VERSION ""

NS_ :

BS_:

BU_: XXX

CM_ "2023 Toyota Corolla (TSS 3.0) powertrain -- CAN FD + SecOC.";
CM_ "STATUS: every bit position below is DECODED FROM PASSIVE RLOGS, NOT CONFIRMED.";
CM_ "Validate in cabana against a real rlog before trusting any value. See NOTES.md.";
CM_ "Bit convention: big-endian (@0) value at byte K -> startbit = K*8 + 7.";
CM_ "SECOC_SYNCHRONIZATION copied verbatim from opendbc toyota_secoc_pt.dbc -- do not hand-edit.";
CM_ "DBC name MUST keep the toyota_ prefix: opendbc auto-computes the CHECKSUM signal off it.";

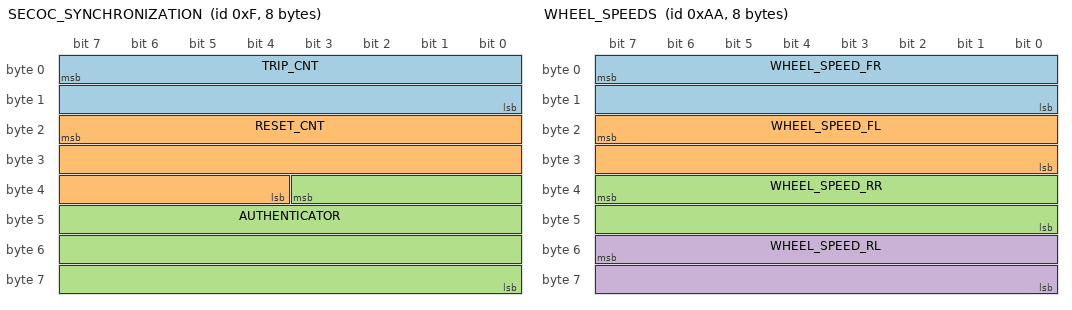
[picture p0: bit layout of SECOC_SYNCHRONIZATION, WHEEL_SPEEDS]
BO_ 15 SECOC_SYNCHRONIZATION: 8 XXX
 SG_ TRIP_CNT : 7|16@0+ (1,0) [0|65535] "" XXX
 SG_ RESET_CNT : 23|20@0+ (1,0) [0|65535] "" XXX
 SG_ AUTHENTICATOR : 35|28@0+ (1,0) [0|268435455] "" XXX

BO_ 48 STEER_ANGLE_SENSOR: 32 XXX
 SG_ STEER_ANGLE : 167|16@0- (0.061,0) [-500|500] "deg" XXX

BO_ 138 STEER_ANGLE_ACC_STATUS: 32 XXX
 SG_ STEER_ANGLE : 151|16@0- (0.061,0) [-500|500] "deg" XXX
 SG_ BYTE24_UNKNOWN : 199|8@0+ (1,0) [0|255] "" XXX
 SG_ ACC_STATE : 63|8@0+ (1,0) [0|255] "" XXX
 SG_ ACC_STANDSTILL : 61|1@0+ (1,0) [0|1] "" XXX
 SG_ ACC_ENGAGED : 180|1@0+ (1,0) [0|1] "" XXX
 SG_ ACC_BUTTON : 167|1@0+ (1,0) [0|1] "" XXX
 SG_ MSG_CNT : 215|8@0+ (1,0) [0|255] "" XXX
 SG_ MAC : 231|32@0+ (1,0) [0|4294967295] "" XXX

BO_ 144 KINEMATICS: 32 XXX
 SG_ YAW_RATE : 100|12@0- (0.02,0) [-100|100] "deg/s" XXX

BO_ 170 WHEEL_SPEEDS: 8 XXX
 SG_ WHEEL_SPEED_FR : 7|16@0+ (0.01,-67.67) [0|250] "km/h" XXX
 SG_ WHEEL_SPEED_FL : 23|16@0+ (0.01,-67.67) [0|250] "km/h" XXX
 SG_ WHEEL_SPEED_RR : 39|16@0+ (0.01,-67.67) [0|250] "km/h" XXX
 SG_ WHEEL_SPEED_RL : 55|16@0+ (0.01,-67.67) [0|250] "km/h" XXX

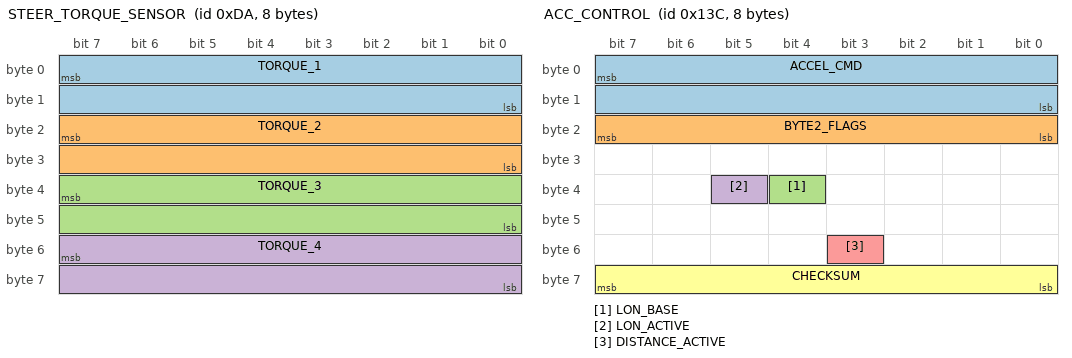
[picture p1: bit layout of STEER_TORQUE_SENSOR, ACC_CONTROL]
BO_ 218 STEER_TORQUE_SENSOR: 8 XXX
 SG_ TORQUE_1 : 7|16@0- (1,0) [-32768|32767] "" XXX
 SG_ TORQUE_2 : 23|16@0- (1,0) [-32768|32767] "" XXX
 SG_ TORQUE_3 : 39|16@0- (1,0) [-32768|32767] "" XXX
 SG_ TORQUE_4 : 55|16@0- (1,0) [-32768|32767] "" XXX

BO_ 278 GAS_PEDAL: 8 XXX
 SG_ GAS_PEDAL_USER : 15|8@0+ (1,0) [0|255] "" XXX

BO_ 257 BRAKE_MODULE: 8 XXX
 SG_ BRAKE_PRESSED : 3|1@0+ (1,0) [0|1] "" XXX
 SG_ BRAKE_PRESSURE : 23|16@0+ (1,0) [0|4095] "" XXX

BO_ 275 ACC_HUD_LEGACY: 8 XXX
 SG_ SET_SPEED : 23|8@0+ (1,0) [0|255] "" XXX

BO_ 316 ACC_CONTROL: 8 XXX
 SG_ ACCEL_CMD : 7|16@0- (0.001,0) [-3.0|1.5] "m/s^2" XXX
 SG_ BYTE2_FLAGS : 23|8@0+ (1,0) [0|255] "" XXX
 SG_ LON_BASE : 36|1@0+ (1,0) [0|1] "" XXX
 SG_ LON_ACTIVE : 37|1@0+ (1,0) [0|1] "" XXX
 SG_ DISTANCE_ACTIVE : 51|1@0+ (1,0) [0|1] "" XXX
 SG_ CHECKSUM : 63|8@0+ (1,0) [0|255] "" XXX

BO_ 593 ACC_HUD: 8 XXX
 SG_ SET_SPEED : 23|8@0+ (1,0) [0|255] "" XXX
 SG_ ACC_ENGAGED_HUD : 6|1@0+ (1,0) [0|1] "" XXX

BO_ 673 GEAR_PACKET: 8 XXX
 SG_ GEAR : 39|8@0+ (1,0) [0|255] "" XXX

BO_ 959 GEAR_PACKET_2: 8 XXX
 SG_ GEAR : 7|8@0+ (1,0) [0|255] "" XXX

BO_ 416 ADAS_STEER_COMMAND: 48 XXX
 SG_ STEER_ANGLE_CMD : 95|16@0- (0.0148,0) [-485|485] "deg" XXX
 SG_ STEER_REQUEST : 54|1@0+ (1,0) [0|1] "" XXX
 SG_ COUNTER : 23|8@0+ (1,0) [0|255] "" XXX
 SG_ BYTE00 : 7|8@0+ (1,0) [0|255] "" XXX
 SG_ BYTE01 : 15|8@0+ (1,0) [0|255] "" XXX
 SG_ BYTE02 : 23|8@0+ (1,0) [0|255] "" XXX
 SG_ BYTE03 : 31|8@0+ (1,0) [0|255] "" XXX
 SG_ BYTE04 : 39|8@0+ (1,0) [0|255] "" XXX
 SG_ BYTE05 : 47|8@0+ (1,0) [0|255] "" XXX
 SG_ BYTE06 : 55|8@0+ (1,0) [0|255] "" XXX
 SG_ BYTE07 : 63|8@0+ (1,0) [0|255] "" XXX
 SG_ BYTE08 : 71|8@0+ (1,0) [0|255] "" XXX
 SG_ BYTE09 : 79|8@0+ (1,0) [0|255] "" XXX
 SG_ BYTE10 : 87|8@0+ (1,0) [0|255] "" XXX
 SG_ BYTE11 : 95|8@0+ (1,0) [0|255] "" XXX
 SG_ BYTE12 : 103|8@0+ (1,0) [0|255] "" XXX
 SG_ BYTE13 : 111|8@0+ (1,0) [0|255] "" XXX
 SG_ BYTE14 : 119|8@0+ (1,0) [0|255] "" XXX
 SG_ BYTE15 : 127|8@0+ (1,0) [0|255] "" XXX
 SG_ BYTE16 : 135|8@0+ (1,0) [0|255] "" XXX
 SG_ BYTE17 : 143|8@0+ (1,0) [0|255] "" XXX
 SG_ BYTE18 : 151|8@0+ (1,0) [0|255] "" XXX
 SG_ BYTE19 : 159|8@0+ (1,0) [0|255] "" XXX
 SG_ BYTE20 : 167|8@0+ (1,0) [0|255] "" XXX
 SG_ BYTE21 : 175|8@0+ (1,0) [0|255] "" XXX
 SG_ BYTE22 : 183|8@0+ (1,0) [0|255] "" XXX
 SG_ BYTE23 : 191|8@0+ (1,0) [0|255] "" XXX
 SG_ BYTE24 : 199|8@0+ (1,0) [0|255] "" XXX
 SG_ BYTE25 : 207|8@0+ (1,0) [0|255] "" XXX
 SG_ BYTE26 : 215|8@0+ (1,0) [0|255] "" XXX
 SG_ BYTE27 : 223|8@0+ (1,0) [0|255] "" XXX
 SG_ BYTE28 : 231|8@0+ (1,0) [0|255] "" XXX
 SG_ BYTE29 : 239|8@0+ (1,0) [0|255] "" XXX
 SG_ BYTE30 : 247|8@0+ (1,0) [0|255] "" XXX
 SG_ BYTE31 : 255|8@0+ (1,0) [0|255] "" XXX
 SG_ BYTE32 : 263|8@0+ (1,0) [0|255] "" XXX
 SG_ BYTE33 : 271|8@0+ (1,0) [0|255] "" XXX
 SG_ BYTE34 : 279|8@0+ (1,0) [0|255] "" XXX
 SG_ BYTE35 : 287|8@0+ (1,0) [0|255] "" XXX
 SG_ BYTE36 : 295|8@0+ (1,0) [0|255] "" XXX
 SG_ BYTE37 : 303|8@0+ (1,0) [0|255] "" XXX
 SG_ BYTE38 : 311|8@0+ (1,0) [0|255] "" XXX
 SG_ BYTE39 : 319|8@0+ (1,0) [0|255] "" XXX
 SG_ BYTE40 : 327|8@0+ (1,0) [0|255] "" XXX
 SG_ BYTE41 : 335|8@0+ (1,0) [0|255] "" XXX
 SG_ BYTE42 : 343|8@0+ (1,0) [0|255] "" XXX
 SG_ BYTE43 : 351|8@0+ (1,0) [0|255] "" XXX
 SG_ BYTE44 : 359|8@0+ (1,0) [0|255] "" XXX
 SG_ BYTE45 : 367|8@0+ (1,0) [0|255] "" XXX
 SG_ BYTE46 : 375|8@0+ (1,0) [0|255] "" XXX
 SG_ BYTE47 : 383|8@0+ (1,0) [0|255] "" XXX

BO_ 352 ADAS_ACC_REQUEST: 32 XXX
 SG_ ACCEL_REQ : 38|15@0- (0.001,0) [-16.384|16.383] "m/s^2" XXX
 SG_ COUNTER : 23|8@0+ (1,0) [0|255] "" XXX
 SG_ BYTE00 : 7|8@0+ (1,0) [0|255] "" XXX
 SG_ BYTE01 : 15|8@0+ (1,0) [0|255] "" XXX
 SG_ BYTE02 : 23|8@0+ (1,0) [0|255] "" XXX
 SG_ BYTE03 : 31|8@0+ (1,0) [0|255] "" XXX
 SG_ BYTE04 : 39|8@0+ (1,0) [0|255] "" XXX
 SG_ BYTE05 : 47|8@0+ (1,0) [0|255] "" XXX
 SG_ BYTE06 : 55|8@0+ (1,0) [0|255] "" XXX
 SG_ BYTE07 : 63|8@0+ (1,0) [0|255] "" XXX
 SG_ BYTE08 : 71|8@0+ (1,0) [0|255] "" XXX
 SG_ BYTE09 : 79|8@0+ (1,0) [0|255] "" XXX
 SG_ BYTE10 : 87|8@0+ (1,0) [0|255] "" XXX
 SG_ BYTE11 : 95|8@0+ (1,0) [0|255] "" XXX
 SG_ BYTE12 : 103|8@0+ (1,0) [0|255] "" XXX
 SG_ BYTE13 : 111|8@0+ (1,0) [0|255] "" XXX
 SG_ BYTE14 : 119|8@0+ (1,0) [0|255] "" XXX
 SG_ BYTE15 : 127|8@0+ (1,0) [0|255] "" XXX
 SG_ BYTE16 : 135|8@0+ (1,0) [0|255] "" XXX
 SG_ BYTE17 : 143|8@0+ (1,0) [0|255] "" XXX
 SG_ BYTE18 : 151|8@0+ (1,0) [0|255] "" XXX
 SG_ BYTE19 : 159|8@0+ (1,0) [0|255] "" XXX
 SG_ BYTE20 : 167|8@0+ (1,0) [0|255] "" XXX
 SG_ BYTE21 : 175|8@0+ (1,0) [0|255] "" XXX
 SG_ BYTE22 : 183|8@0+ (1,0) [0|255] "" XXX
 SG_ BYTE23 : 191|8@0+ (1,0) [0|255] "" XXX
 SG_ BYTE24 : 199|8@0+ (1,0) [0|255] "" XXX
 SG_ BYTE25 : 207|8@0+ (1,0) [0|255] "" XXX
 SG_ BYTE26 : 215|8@0+ (1,0) [0|255] "" XXX
 SG_ BYTE27 : 223|8@0+ (1,0) [0|255] "" XXX
 SG_ BYTE28 : 231|8@0+ (1,0) [0|255] "" XXX
 SG_ BYTE29 : 239|8@0+ (1,0) [0|255] "" XXX
 SG_ BYTE30 : 247|8@0+ (1,0) [0|255] "" XXX
 SG_ BYTE31 : 255|8@0+ (1,0) [0|255] "" XXX

VAL_ 673 GEAR 1 "P" 2 "R" 4 "D" 8 "N" ;
VAL_ 959 GEAR 128 "P" 64 "R" 16 "D" 32 "N" ;

CM_ SG_ 138 MSG_CNT "byte 26, SecOC message counter.";
CM_ SG_ 138 MAC "bytes 28-31 per the port doc. opendbc's 8-byte SecOC scheme splits this as a 4-bit flags nibble + 28-bit AUTHENTICATOR, so the real split here is likely 4+28, not a flat 32. Unresolved -- only matters for Phase 2 signing.";
CM_ SG_ 144 YAW_RATE "12-bit signed, MSB-first stream bit 99 -> DBC startbit 100. ~50 raw/deg-per-s. UNVERIFIED CONVERSION.";
CM_ SG_ 170 WHEEL_SPEED_FR "Legacy Toyota layout+scale. Wheel-to-corner assignment NOT verified -- confirm inner/outer in a turn.";
CM_ SG_ 218 TORQUE_1 "0xDA is 42 Hz, no MAC, four int16. Which field is driver torque vs EPS torque is UNKNOWN.";
CM_ SG_ 257 BRAKE_PRESSED "byte 0 bit 3 (0x80 -> 0x88). r=0.85 vs decel.";
CM_ SG_ 257 BRAKE_PRESSURE "bytes 2-3, observed 0-410 raw. Raw counts, no scale established.";
CM_ SG_ 275 SET_SPEED "LOW CONFIDENCE: held 27 (mph?) and never changed in any log.";
CM_ SG_ 316 ACCEL_CMD "bytes 0-1 int16 BE, 0.001 m/s^2/count. Observed -1.56..+2.37 m/s^2. Plaintext, bus 0, 20 Hz.";
CM_ SG_ 316 BYTE2_FLAGS "byte 2, constant 0xFF in this dataset. NOT the legacy 2-bit ACC_TYPE: on classic Toyota 0x343 all the flag bits live in bytes 2-3, here they are in bytes 4 and 6, so legacy names do not map positionally. Left as one opaque byte rather than invented sub-signals.";
CM_ SG_ 316 LON_BASE "byte 4 mask 0x10. The doc's \"0x10 base\" bit -- set in EVERY observed frame, so the packer must set it too or byte 4 goes out as 0x20 instead of 0x30. Meaning unknown.";
CM_ SG_ 316 LON_ACTIVE "byte 4 mask 0x20 (0x10 base -> 0x30 controlling). NOTE: doc said startbit 45, byte 4 mask 0x20 is startbit 37.";
CM_ SG_ 316 DISTANCE_ACTIVE "byte 6 mask 0x08. NOTE: doc said startbit 60, that lands in byte 7 (checksum); byte 6 mask 0x08 is startbit 51.";
CM_ SG_ 316 CHECKSUM "Standard Toyota checksum, verified 4799/4799. Name must stay CHECKSUM so opendbc auto-computes it on pack.";
CM_ SG_ 673 GEAR "byte 4, one-hot. N=0x08 inferred (never observed).";
CM_ SG_ 959 GEAR "byte 0. Mirrors 0x2A1 byte 4. N=0x20 inferred (never observed).";

CM_ SG_ 138 ACC_STATE "byte 7. DECODED FROM REAL DRIVES: 0x12 = not engaged, 0x47 = engaged, 0x67 = engaged + standstill hold. Leads 0x13C.LON_ACTIVE by ~100ms so it reports DRIVER INTENT and survives openpilot taking over 0x13C. Bit 0x01 pulses during the standstill release handshake (0x67 -> 0x66 -> 0x46 -> 0x47), meaning unknown.";
CM_ SG_ 138 ACC_ENGAGED "byte 22 mask 0x10. Cleanest single bit: exactly two values across the whole drive (0x00 / 0x10), 40 Hz, 99.67% agreement with 0x13C LON_ACTIVE (the 0.33% is the 100ms lead). THIS is what cruiseState.enabled should use, NOT 0x13C.";
CM_ SG_ 138 ACC_BUTTON "byte 20 mask 0x80. Pulses on cruise button presses (+/-). Byte 20 is 0xc0 while engaged and dips to 0x40 per press.";
CM_ SG_ 593 SET_SPEED "byte 2, mph, factor 1.0 -- the raw byte is the number on the dash (confirmed 2026-09-09). Increments/decrements exactly one per +/- press. RETAINED while disengaged: engaging with +/- resumes the PREVIOUS set speed rather than the current speed (observed resuming at 25 mph while rolling at 3.6 mph), whereas the ACC main button engages at the current speed. Floors at 19 mph. The port doc guessed 0x113 byte 2, which held constant because nobody had adjusted the speed while logging.";
CM_ SG_ 593 ACC_ENGAGED_HUD "byte 0 mask 0x40. Cluster copy of engaged, but 0x251 is only ~1.3 Hz -- too slow for engagement logic. Use 0x8A ACC_ENGAGED instead.";
CM_ SG_ 138 BYTE24_UNKNOWN "byte 24. The port doc section 4 calls this ACC_MAIN_ON (0/100). DISPROVED on the 2026-09-09 drive: read 0x00 for all 7232 frames of a drive in which ACC was ENGAGED three separate times, which is impossible with the main system off. This byte is not ACC main on. Kept only to document the dead end -- use ACC_STATE.";
CM_ SG_ 48 STEER_ANGLE "bytes 20-21, int16 BE. Identical raw values to 0x8A bytes 18-19.";
CM_ SG_ 138 STEER_ANGLE "bytes 18-19, int16 BE, 0.061 deg/count. VALIDATED ON THE CAR 2026-09-09: during a turnaround the raw value moves smoothly and SATURATES at -8211 for over a second -- the mechanical steering lock. -8211 * 0.061 = -500.9 deg, i.e. ~2.8 turns lock to lock, correct for a Corolla. The port doc fitted 0.061 then multiplied by steerRatio to get 0.84; that was wrong, the fit already gave the STEERING WHEEL angle. steerRatio 13.9 is independent and gives ~36 deg at the road wheel at full lock, which is also correct. Positive = left per the doc, not re-verified.";
CM_ SG_ 138 ACC_STANDSTILL "byte 7 mask 0x20. ACC engaged and holding the car at a stop behind a lead vehicle, waiting for gas or RES. Captured 2026-09-09: 492 frames (~12s) at 0.0 kph, released cleanly. This is what cruiseState.standstill must read -- port doc 12.2 item 1, RECEIVE side now solved. NOTE the TRANSMIT side is still unknown: openpilot would need the release/hold bits inside 0x13C to command a resume, and those have not been identified. So this makes the state readable, not yet commandable.";
CM_ BO_ 352 "0x160 ADAS_ACC_REQUEST -- the FRONT CAMERA's acceleration request, 32-byte CAN FD, 40 Hz, on the ADAS bus (relayed pair, panda bus 0<->2). Proven camera-sourced by the 2026-09-09 unplug test (vanished when the camera was disconnected). This is the message openpilot REPLACES for longitudinal, not 0x13C: the camera asks here, a gateway filters it into 0x13C on the powertrain bus.";
CM_ SG_ 352 ACCEL_REQ "bits 33-47, 15-bit signed big-endian, 0.001 m/s^2. r=0.992 vs 0x13C.ACCEL_CMD over 3807 engaged samples; range -2.55..+2.41 observed. byte4 bit7 (0x80) is a SEPARATE constant=1 flag above the field -- do not clobber it (BYTE04 preserves it).";
CM_ SG_ 352 COUNTER "byte 2, rolling +1 mod 256. Part of the AUTOSAR E2E protection.";
CM_ SG_ 352 BYTE00 "bytes 0-1 are the E2E CRC-16/CCITT (little-endian), NOT a toyota_ checksum. Computed by e2e.py over BYTE02..31 + DataID 0x444A. Verified 26290/26290 frames across two sessions. BYTE00..31 exist so carState can reconstruct the exact frame for modify-and-forward.";
CM_ SG_ 278 GAS_PEDAL_USER "0x116 byte 1, on the powertrain bus (bus 1). The driver gas pedal, 0..~154 observed, 0 at rest and 100% zero while braking (verified route 16). Byte 0 mirrors it. This is the exact address+byte the panda SecOC path already reads for gas on Toyota. gasPressed = value != 0 (rest is a true 0).";
CM_ BO_ 416 "0x1A0 ADAS_STEER_COMMAND -- the LTA steering command, 48-byte CAN FD, on the ADAS bus (relayed, panda bus 0/2). Gateway-sent (survives camera unplug), EPS executes it. IDENTIFIED by: idle when LTA off, SecOC/E2E-framed (only secured msg in the candidate set), request bit + angle field. openpilot REPLACES this for lateral.";
CM_ SG_ 416 STEER_ANGLE_CMD "byte 11-12, 16-bit signed BE, ~0.0148 deg/count. Angle-based (corr 0.83 vs measured angle, ~0 vs rate). LTA authority ~+/-17 deg observed.";
CM_ SG_ 416 STEER_REQUEST "byte 6 bit 6. 86% set when LTA steering, ~1% when off.";
CM_ SG_ 416 COUNTER "byte 2, E2E rolling counter. bytes 0-1 = E2E CRC-16/CCITT (LE), DataID 0xBEA8 -- KEYLESS, same scheme as 0x160 (DataID 0x444A). Computed by e2e.apply_e2e_1a0.";

CM_ "TSS3 front-radar object banks (0x180-0x185) ported from kaikozlov/opendbc generator/toyota/toyota_tss3_pt.dbc for lead detection.";
BO_ 384 TSS3_OBJECT_GEOMETRY_0: 64 XXX
 SG_ CHECKSUM : 0|16@1+ (1,0) [0|65535] "" XXX
 SG_ COUNTER : 16|8@1+ (1,0) [0|255] "" XXX
 SG_ CYCLE_BYTE : 24|8@1+ (1,0) [0|255] "" XXX
 SG_ DIST_0 : 39|16@0+ (0.005,0) [0|327.675] "m" XXX
 SG_ LAT_0 : 55|12@0- (0.04,0) [-81.92|81.88] "m" XXX
 SG_ DIST_1 : 95|16@0+ (0.005,0) [0|327.675] "m" XXX
 SG_ LAT_1 : 111|12@0- (0.04,0) [-81.92|81.88] "m" XXX
 SG_ DIST_2 : 151|16@0+ (0.005,0) [0|327.675] "m" XXX
 SG_ LAT_2 : 167|12@0- (0.04,0) [-81.92|81.88] "m" XXX
 SG_ DIST_3 : 207|16@0+ (0.005,0) [0|327.675] "m" XXX
 SG_ LAT_3 : 223|12@0- (0.04,0) [-81.92|81.88] "m" XXX
 SG_ DIST_4 : 263|16@0+ (0.005,0) [0|327.675] "m" XXX
 SG_ LAT_4 : 279|12@0- (0.04,0) [-81.92|81.88] "m" XXX
 SG_ DIST_5 : 319|16@0+ (0.005,0) [0|327.675] "m" XXX
 SG_ LAT_5 : 335|12@0- (0.04,0) [-81.92|81.88] "m" XXX
 SG_ DIST_6 : 375|16@0+ (0.005,0) [0|327.675] "m" XXX
 SG_ LAT_6 : 391|12@0- (0.04,0) [-81.92|81.88] "m" XXX
 SG_ DIST_7 : 431|16@0+ (0.005,0) [0|327.675] "m" XXX
 SG_ LAT_7 : 447|12@0- (0.04,0) [-81.92|81.88] "m" XXX

BO_ 385 TSS3_OBJECT_GEOMETRY_1: 64 XXX
 SG_ CHECKSUM : 0|16@1+ (1,0) [0|65535] "" XXX
 SG_ COUNTER : 16|8@1+ (1,0) [0|255] "" XXX
 SG_ CYCLE_BYTE : 24|8@1+ (1,0) [0|255] "" XXX
 SG_ DIST_0 : 39|16@0+ (0.005,0) [0|327.675] "m" XXX
 SG_ LAT_0 : 55|12@0- (0.04,0) [-81.92|81.88] "m" XXX
 SG_ DIST_1 : 95|16@0+ (0.005,0) [0|327.675] "m" XXX
 SG_ LAT_1 : 111|12@0- (0.04,0) [-81.92|81.88] "m" XXX
 SG_ DIST_2 : 151|16@0+ (0.005,0) [0|327.675] "m" XXX
 SG_ LAT_2 : 167|12@0- (0.04,0) [-81.92|81.88] "m" XXX
 SG_ DIST_3 : 207|16@0+ (0.005,0) [0|327.675] "m" XXX
 SG_ LAT_3 : 223|12@0- (0.04,0) [-81.92|81.88] "m" XXX
 SG_ DIST_4 : 263|16@0+ (0.005,0) [0|327.675] "m" XXX
 SG_ LAT_4 : 279|12@0- (0.04,0) [-81.92|81.88] "m" XXX
 SG_ DIST_5 : 319|16@0+ (0.005,0) [0|327.675] "m" XXX
 SG_ LAT_5 : 335|12@0- (0.04,0) [-81.92|81.88] "m" XXX
 SG_ DIST_6 : 375|16@0+ (0.005,0) [0|327.675] "m" XXX
 SG_ LAT_6 : 391|12@0- (0.04,0) [-81.92|81.88] "m" XXX
 SG_ DIST_7 : 431|16@0+ (0.005,0) [0|327.675] "m" XXX
 SG_ LAT_7 : 447|12@0- (0.04,0) [-81.92|81.88] "m" XXX

BO_ 386 TSS3_OBJECT_GEOMETRY_2: 64 XXX
 SG_ CHECKSUM : 0|16@1+ (1,0) [0|65535] "" XXX
 SG_ COUNTER : 16|8@1+ (1,0) [0|255] "" XXX
 SG_ CYCLE_BYTE : 24|8@1+ (1,0) [0|255] "" XXX
 SG_ DIST_0 : 39|16@0+ (0.005,0) [0|327.675] "m" XXX
 SG_ LAT_0 : 55|12@0- (0.04,0) [-81.92|81.88] "m" XXX
 SG_ DIST_1 : 95|16@0+ (0.005,0) [0|327.675] "m" XXX
 SG_ LAT_1 : 111|12@0- (0.04,0) [-81.92|81.88] "m" XXX
 SG_ DIST_2 : 151|16@0+ (0.005,0) [0|327.675] "m" XXX
 SG_ LAT_2 : 167|12@0- (0.04,0) [-81.92|81.88] "m" XXX
 SG_ DIST_3 : 207|16@0+ (0.005,0) [0|327.675] "m" XXX
 SG_ LAT_3 : 223|12@0- (0.04,0) [-81.92|81.88] "m" XXX
 SG_ DIST_4 : 263|16@0+ (0.005,0) [0|327.675] "m" XXX
 SG_ LAT_4 : 279|12@0- (0.04,0) [-81.92|81.88] "m" XXX
 SG_ DIST_5 : 319|16@0+ (0.005,0) [0|327.675] "m" XXX
 SG_ LAT_5 : 335|12@0- (0.04,0) [-81.92|81.88] "m" XXX
 SG_ DIST_6 : 375|16@0+ (0.005,0) [0|327.675] "m" XXX
 SG_ LAT_6 : 391|12@0- (0.04,0) [-81.92|81.88] "m" XXX
 SG_ DIST_7 : 431|16@0+ (0.005,0) [0|327.675] "m" XXX
 SG_ LAT_7 : 447|12@0- (0.04,0) [-81.92|81.88] "m" XXX

BO_ 387 TSS3_OBJECT_MOTION_0: 64 XXX
 SG_ CHECKSUM : 0|16@1+ (1,0) [0|65535] "" XXX
 SG_ COUNTER : 16|8@1+ (1,0) [0|255] "" XXX
 SG_ CYCLE_BYTE : 24|8@1+ (1,0) [0|255] "" XXX
 SG_ VREL_0 : 45|14@0- (0.025,0) [-204.8|204.775] "m/s" XXX
 SG_ VREL_1 : 101|14@0- (0.025,0) [-204.8|204.775] "m/s" XXX
 SG_ VREL_2 : 157|14@0- (0.025,0) [-204.8|204.775] "m/s" XXX
 SG_ VREL_3 : 213|14@0- (0.025,0) [-204.8|204.775] "m/s" XXX
 SG_ VREL_4 : 269|14@0- (0.025,0) [-204.8|204.775] "m/s" XXX
 SG_ VREL_5 : 325|14@0- (0.025,0) [-204.8|204.775] "m/s" XXX
 SG_ VREL_6 : 381|14@0- (0.025,0) [-204.8|204.775] "m/s" XXX
 SG_ VREL_7 : 437|14@0- (0.025,0) [-204.8|204.775] "m/s" XXX
 SG_ NEW_TRACK_0 : 71|1@0+ (1,0) [0|1] "" XXX
 SG_ TRACK_ENDED_0 : 76|1@0+ (1,0) [0|1] "" XXX
 SG_ TRACK_STATE_0 : 73|2@0+ (1,0) [0|3] "" XXX
 SG_ NEW_TRACK_1 : 127|1@0+ (1,0) [0|1] "" XXX
 SG_ TRACK_ENDED_1 : 132|1@0+ (1,0) [0|1] "" XXX
 SG_ TRACK_STATE_1 : 129|2@0+ (1,0) [0|3] "" XXX
 SG_ NEW_TRACK_2 : 183|1@0+ (1,0) [0|1] "" XXX
 SG_ TRACK_ENDED_2 : 188|1@0+ (1,0) [0|1] "" XXX
 SG_ TRACK_STATE_2 : 185|2@0+ (1,0) [0|3] "" XXX
 SG_ NEW_TRACK_3 : 239|1@0+ (1,0) [0|1] "" XXX
 SG_ TRACK_ENDED_3 : 244|1@0+ (1,0) [0|1] "" XXX
 SG_ TRACK_STATE_3 : 241|2@0+ (1,0) [0|3] "" XXX
 SG_ NEW_TRACK_4 : 295|1@0+ (1,0) [0|1] "" XXX
 SG_ TRACK_ENDED_4 : 300|1@0+ (1,0) [0|1] "" XXX
 SG_ TRACK_STATE_4 : 297|2@0+ (1,0) [0|3] "" XXX
 SG_ NEW_TRACK_5 : 351|1@0+ (1,0) [0|1] "" XXX
 SG_ TRACK_ENDED_5 : 356|1@0+ (1,0) [0|1] "" XXX
 SG_ TRACK_STATE_5 : 353|2@0+ (1,0) [0|3] "" XXX
 SG_ NEW_TRACK_6 : 407|1@0+ (1,0) [0|1] "" XXX
 SG_ TRACK_ENDED_6 : 412|1@0+ (1,0) [0|1] "" XXX
 SG_ TRACK_STATE_6 : 409|2@0+ (1,0) [0|3] "" XXX
 SG_ NEW_TRACK_7 : 463|1@0+ (1,0) [0|1] "" XXX
 SG_ TRACK_ENDED_7 : 468|1@0+ (1,0) [0|1] "" XXX
 SG_ TRACK_STATE_7 : 465|2@0+ (1,0) [0|3] "" XXX

BO_ 388 TSS3_OBJECT_MOTION_1: 64 XXX
 SG_ CHECKSUM : 0|16@1+ (1,0) [0|65535] "" XXX
 SG_ COUNTER : 16|8@1+ (1,0) [0|255] "" XXX
 SG_ CYCLE_BYTE : 24|8@1+ (1,0) [0|255] "" XXX
 SG_ VREL_0 : 45|14@0- (0.025,0) [-204.8|204.775] "m/s" XXX
 SG_ VREL_1 : 101|14@0- (0.025,0) [-204.8|204.775] "m/s" XXX
 SG_ VREL_2 : 157|14@0- (0.025,0) [-204.8|204.775] "m/s" XXX
 SG_ VREL_3 : 213|14@0- (0.025,0) [-204.8|204.775] "m/s" XXX
 SG_ VREL_4 : 269|14@0- (0.025,0) [-204.8|204.775] "m/s" XXX
 SG_ VREL_5 : 325|14@0- (0.025,0) [-204.8|204.775] "m/s" XXX
 SG_ VREL_6 : 381|14@0- (0.025,0) [-204.8|204.775] "m/s" XXX
 SG_ VREL_7 : 437|14@0- (0.025,0) [-204.8|204.775] "m/s" XXX
 SG_ NEW_TRACK_0 : 71|1@0+ (1,0) [0|1] "" XXX
 SG_ TRACK_ENDED_0 : 76|1@0+ (1,0) [0|1] "" XXX
 SG_ TRACK_STATE_0 : 73|2@0+ (1,0) [0|3] "" XXX
 SG_ NEW_TRACK_1 : 127|1@0+ (1,0) [0|1] "" XXX
 SG_ TRACK_ENDED_1 : 132|1@0+ (1,0) [0|1] "" XXX
 SG_ TRACK_STATE_1 : 129|2@0+ (1,0) [0|3] "" XXX
 SG_ NEW_TRACK_2 : 183|1@0+ (1,0) [0|1] "" XXX
 SG_ TRACK_ENDED_2 : 188|1@0+ (1,0) [0|1] "" XXX
 SG_ TRACK_STATE_2 : 185|2@0+ (1,0) [0|3] "" XXX
 SG_ NEW_TRACK_3 : 239|1@0+ (1,0) [0|1] "" XXX
 SG_ TRACK_ENDED_3 : 244|1@0+ (1,0) [0|1] "" XXX
 SG_ TRACK_STATE_3 : 241|2@0+ (1,0) [0|3] "" XXX
 SG_ NEW_TRACK_4 : 295|1@0+ (1,0) [0|1] "" XXX
 SG_ TRACK_ENDED_4 : 300|1@0+ (1,0) [0|1] "" XXX
 SG_ TRACK_STATE_4 : 297|2@0+ (1,0) [0|3] "" XXX
 SG_ NEW_TRACK_5 : 351|1@0+ (1,0) [0|1] "" XXX
 SG_ TRACK_ENDED_5 : 356|1@0+ (1,0) [0|1] "" XXX
 SG_ TRACK_STATE_5 : 353|2@0+ (1,0) [0|3] "" XXX
 SG_ NEW_TRACK_6 : 407|1@0+ (1,0) [0|1] "" XXX
 SG_ TRACK_ENDED_6 : 412|1@0+ (1,0) [0|1] "" XXX
 SG_ TRACK_STATE_6 : 409|2@0+ (1,0) [0|3] "" XXX
 SG_ NEW_TRACK_7 : 463|1@0+ (1,0) [0|1] "" XXX
 SG_ TRACK_ENDED_7 : 468|1@0+ (1,0) [0|1] "" XXX
 SG_ TRACK_STATE_7 : 465|2@0+ (1,0) [0|3] "" XXX

BO_ 389 TSS3_OBJECT_MOTION_2: 64 XXX
 SG_ CHECKSUM : 0|16@1+ (1,0) [0|65535] "" XXX
 SG_ COUNTER : 16|8@1+ (1,0) [0|255] "" XXX
 SG_ CYCLE_BYTE : 24|8@1+ (1,0) [0|255] "" XXX
 SG_ VREL_0 : 45|14@0- (0.025,0) [-204.8|204.775] "m/s" XXX
 SG_ VREL_1 : 101|14@0- (0.025,0) [-204.8|204.775] "m/s" XXX
 SG_ VREL_2 : 157|14@0- (0.025,0) [-204.8|204.775] "m/s" XXX
 SG_ VREL_3 : 213|14@0- (0.025,0) [-204.8|204.775] "m/s" XXX
 SG_ VREL_4 : 269|14@0- (0.025,0) [-204.8|204.775] "m/s" XXX
 SG_ VREL_5 : 325|14@0- (0.025,0) [-204.8|204.775] "m/s" XXX
 SG_ VREL_6 : 381|14@0- (0.025,0) [-204.8|204.775] "m/s" XXX
 SG_ VREL_7 : 437|14@0- (0.025,0) [-204.8|204.775] "m/s" XXX
 SG_ NEW_TRACK_0 : 71|1@0+ (1,0) [0|1] "" XXX
 SG_ TRACK_ENDED_0 : 76|1@0+ (1,0) [0|1] "" XXX
 SG_ TRACK_STATE_0 : 73|2@0+ (1,0) [0|3] "" XXX
 SG_ NEW_TRACK_1 : 127|1@0+ (1,0) [0|1] "" XXX
 SG_ TRACK_ENDED_1 : 132|1@0+ (1,0) [0|1] "" XXX
 SG_ TRACK_STATE_1 : 129|2@0+ (1,0) [0|3] "" XXX
 SG_ NEW_TRACK_2 : 183|1@0+ (1,0) [0|1] "" XXX
 SG_ TRACK_ENDED_2 : 188|1@0+ (1,0) [0|1] "" XXX
 SG_ TRACK_STATE_2 : 185|2@0+ (1,0) [0|3] "" XXX
 SG_ NEW_TRACK_3 : 239|1@0+ (1,0) [0|1] "" XXX
 SG_ TRACK_ENDED_3 : 244|1@0+ (1,0) [0|1] "" XXX
 SG_ TRACK_STATE_3 : 241|2@0+ (1,0) [0|3] "" XXX
 SG_ NEW_TRACK_4 : 295|1@0+ (1,0) [0|1] "" XXX
 SG_ TRACK_ENDED_4 : 300|1@0+ (1,0) [0|1] "" XXX
 SG_ TRACK_STATE_4 : 297|2@0+ (1,0) [0|3] "" XXX
 SG_ NEW_TRACK_5 : 351|1@0+ (1,0) [0|1] "" XXX
 SG_ TRACK_ENDED_5 : 356|1@0+ (1,0) [0|1] "" XXX
 SG_ TRACK_STATE_5 : 353|2@0+ (1,0) [0|3] "" XXX
 SG_ NEW_TRACK_6 : 407|1@0+ (1,0) [0|1] "" XXX
 SG_ TRACK_ENDED_6 : 412|1@0+ (1,0) [0|1] "" XXX
 SG_ TRACK_STATE_6 : 409|2@0+ (1,0) [0|3] "" XXX
 SG_ NEW_TRACK_7 : 463|1@0+ (1,0) [0|1] "" XXX
 SG_ TRACK_ENDED_7 : 468|1@0+ (1,0) [0|1] "" XXX
 SG_ TRACK_STATE_7 : 465|2@0+ (1,0) [0|3] "" XXX
